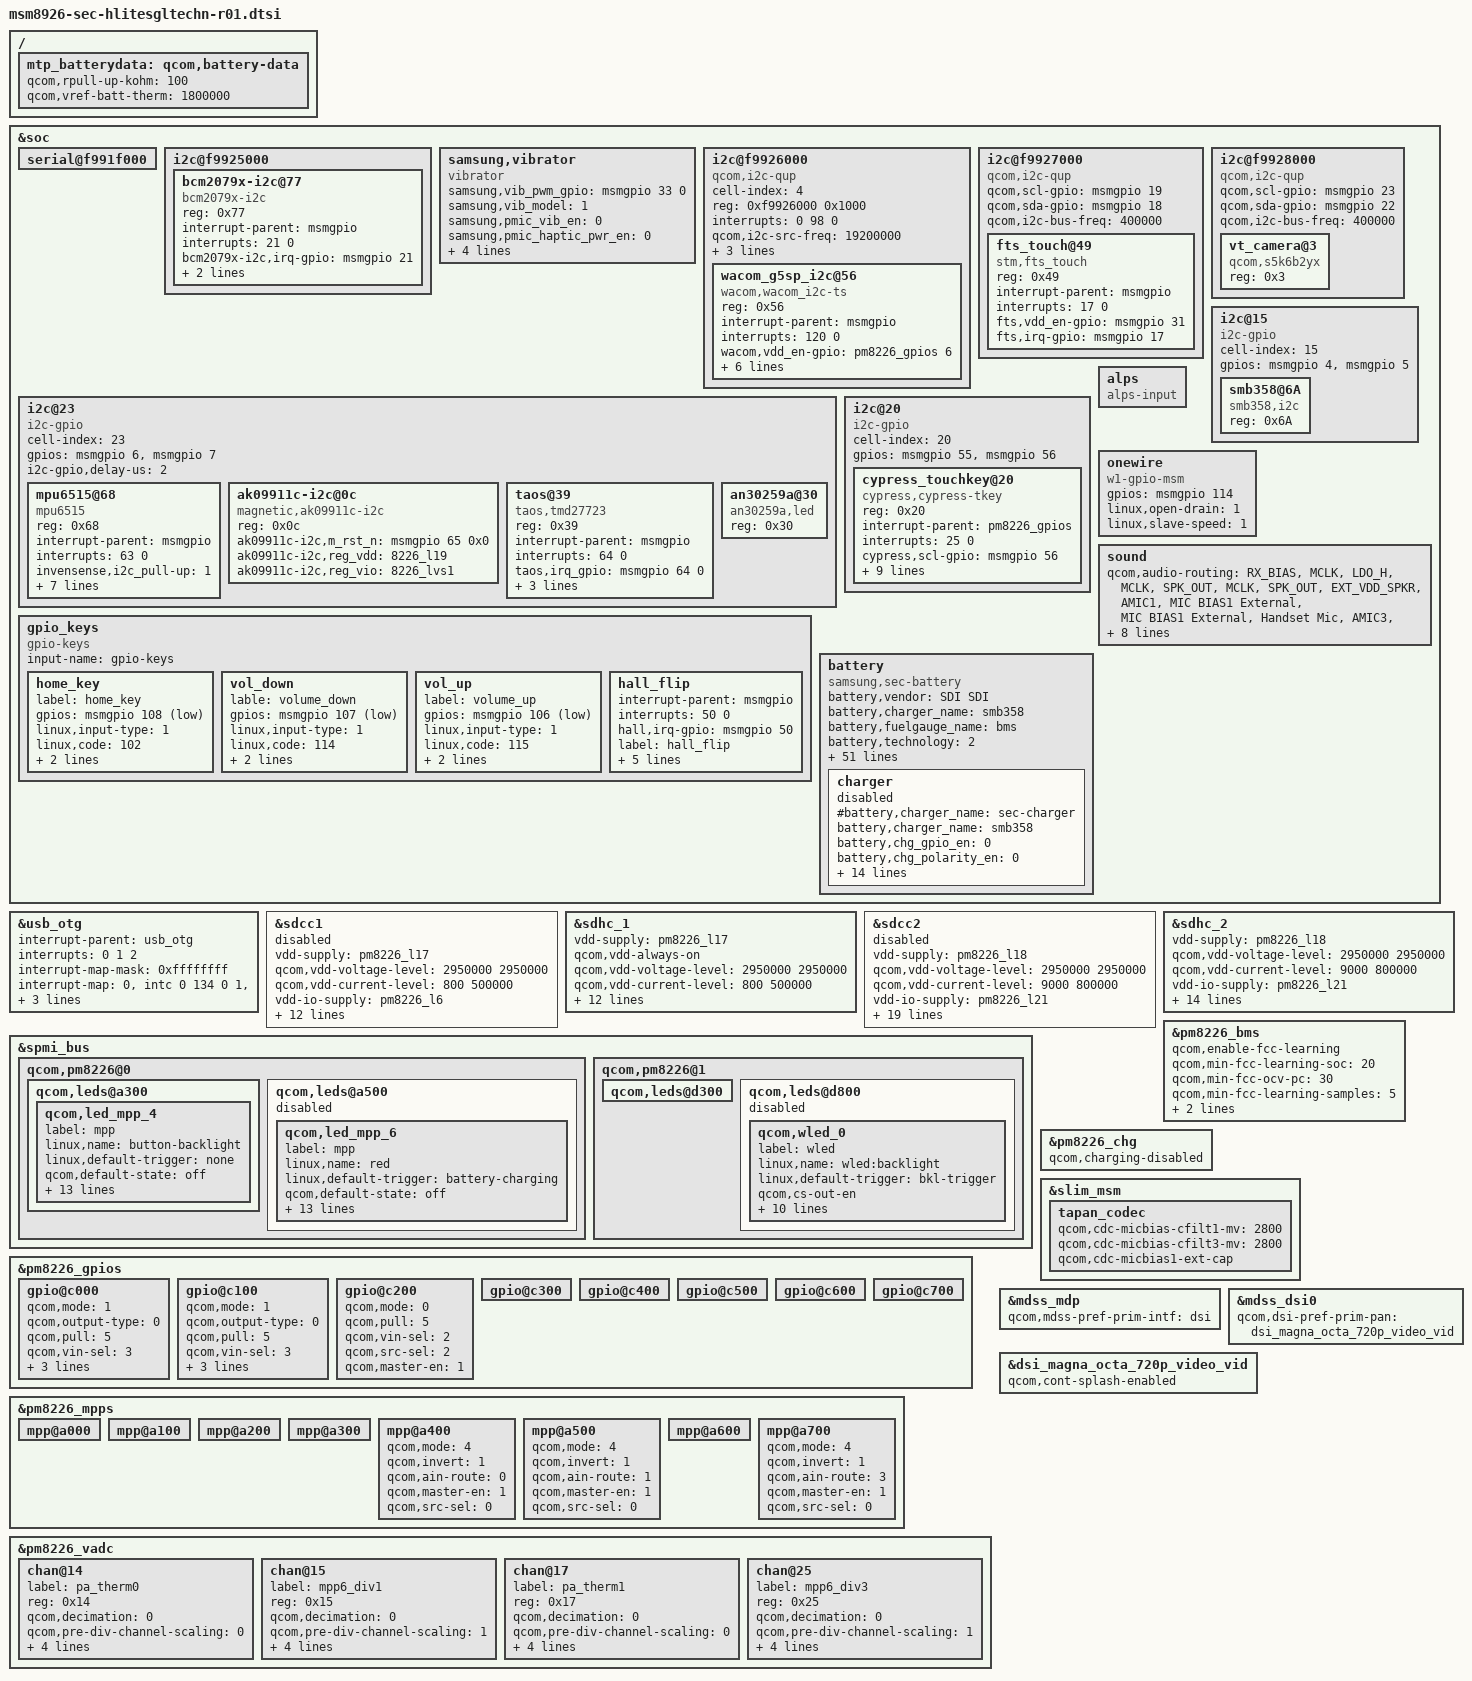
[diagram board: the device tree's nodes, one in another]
/* Copyright (c) 2013, The Linux Foundation. All rights reserved.
 *
 * This program is free software; you can redistribute it and/or modify
 * it under the terms of the GNU General Public License version 2 and
 * only version 2 as published by the Free Software Foundation.
 *
 * This program is distributed in the hope that it will be useful,
 * but WITHOUT ANY WARRANTY; without even the implied warranty of
 * MERCHANTABILITY or FITNESS FOR A PARTICULAR PURPOSE.  See the
 * GNU General Public License for more details.
 */

/include/ "dsi_panel_sharp_720p_video-r01.dtsi"
/include/ "msm8926-camera-sensor-mtp-hllte-r01.dtsi"
/include/ "msm8926-sm5502.dtsi"

&soc {
	serial@f991f000 {
		status = "ok";
	}; 


	i2c@f9925000 {
		bcm2079x-i2c@77 {
			compatible = "bcm2079x-i2c";
			reg = <0x77>;
			interrupt-parent = <&msmgpio>;
           		 interrupts = <21 0>;
			bcm2079x-i2c,irq-gpio = <&msmgpio 21 0x00>;
			bcm2079x-i2c,en-gpio = <&msmgpio 20 0x00>;
			bcm2079x-i2c,wake-gpio = <&msmgpio 62 0x00>;
			};
		};

		samsung,vibrator{
			compatible = "vibrator";
			samsung,vib_pwm_gpio = <&msmgpio 33 0>;
			samsung,vib_model = <1>;
			samsung,pmic_vib_en = <0>;
			samsung,pmic_haptic_pwr_en = <0>;
			samsung,is_pmic_vib_pwm = <0>;
			samsung,is_pmic_vib_en = <0>;
			samsung,pwm_period_us = <40>;
			samsung,duty_us = <36>;
			status = "ok";
    			};
	   
	i2c@f9926000 {
		cell-index = <4>;
		compatible = "qcom,i2c-qup";
		reg = <0xf9926000 0x1000>;
		#address-cells = <1>;
		#size-cells = <0>;
		reg-names = "qup_phys_addr";
		interrupts = <0 98 0>;
		interrupt-names = "qup_err_intr";
		qcom,i2c-src-freq = <19200000>;
		qcom,i2c-bus-freq = <400000>;
		qcom,scl-gpio = <&msmgpio 15 0>;
		qcom,sda-gpio = <&msmgpio 14 0>;
	
		wacom_g5sp_i2c@56 {
			compatible = "wacom,wacom_i2c-ts";
			reg = <0x56>;
			interrupt-parent = <&msmgpio>;
			interrupts = <120 0>;
			wacom,vdd_en-gpio = <&pm8226_gpios 6 0x00>;
			wacom,irq-gpio = <&msmgpio 120 0x00>;
			wacom,insert-pull-up = <1>;
			wacom,sense-gpio = <&msmgpio 54 0x1>;
			wacom,reset_n-gpio = <&msmgpio 13 0x00>;
			wacom,pen_fwe1-gpio = <&msmgpio 119 0x00>;
			wacom,pen_pdct-gpio = <&msmgpio 110 0x00>;
			};
		};

	
	i2c@f9927000 { 
		compatible = "qcom,i2c-qup";
		qcom,scl-gpio = <&msmgpio 19 0>;
		qcom,sda-gpio = <&msmgpio 18 0>;
		qcom,i2c-bus-freq = <400000>;
		fts_touch@49 {
			compatible = "stm,fts_touch";
			reg = <0x49>;
			interrupt-parent = <&msmgpio>;
			interrupts = <17 0>;
			fts,vdd_en-gpio = <&msmgpio 31 0x00>;
			fts,irq-gpio = <&msmgpio 17 0x00>;
			/* vddo-supply = <&pm8226_lvs1>; */
			};
		};
	
		i2c@f9928000 { 
			compatible = "qcom,i2c-qup";
			qcom,scl-gpio = <&msmgpio 23 0>;
			qcom,sda-gpio = <&msmgpio 22 0>;
			qcom,i2c-bus-freq = <400000>;
			vt_camera@3 {
					compatible = "qcom,s5k6b2yx";
					reg = <0x3>;
				};
		};
	
	i2c@23 {
		cell-index = <23>;
		compatible = "i2c-gpio";
		gpios = <&msmgpio 6 0 /* sda */
		&msmgpio 7 0 /* scl */
		>;
                i2c-gpio,delay-us = <2>;
		mpu6515@68 {
			compatible = "mpu6515";
			reg = <0x68>;
			interrupt-parent = <&msmgpio>;
			interrupts = <63 0>;
			invensense,i2c_pull-up = <1>;
			invensense,reg_vdd = "8226_l19";
			invensense,reg_vio = "8226_lvs1";
	             	invensense,irq-gpio= <&msmgpio 63 0x1>;
			invensense,scl-gpio = <&msmgpio 7 0x00>;
			invensense,sda-gpio = <&msmgpio 6 0x00>;
			invensense,acc_cal_path = "/efs/calibration_data";
			invensense,gyro_cal_path = "/efs/gyro_cal_data";
		};
		ak09911c-i2c@0c {
			compatible = "magnetic,ak09911c-i2c";
			reg = <0x0c>;
			ak09911c-i2c,m_rst_n = <&msmgpio 65 0x0>;
			ak09911c-i2c,reg_vdd = "8226_l19";
			ak09911c-i2c,reg_vio = "8226_lvs1";
		};
		taos@39 {
			compatible = "taos,tmd27723";
			reg = <0x39>;
			interrupt-parent = <&msmgpio>;
			interrupts = <64 0>;
			taos,irq_gpio = <&msmgpio 64 0>;
			taos,en = <&pm8226_gpios 8 0x00>;
			taos,prox_cal_path = "/efs/prox_cal";
			taos,vdd_2p85 = "8226_l19";
		};
		an30259a@30 {
			compatible = "an30259a,led";
			reg = <0x30>;
		};
	};
	
	i2c@15 {
		cell-index = <15>;
		compatible = "i2c-gpio";
		gpios = <&msmgpio 4 0  /* sda */
				&msmgpio 5 0   /* scl */
				>;

		smb358@6A {
			compatible = "smb358,i2c";
			reg = <0x6A>;
		};
		};

	i2c@20 {
		cell-index = <20>;
		compatible = "i2c-gpio";
		gpios = <&msmgpio 55 0 /* sda */
		&msmgpio 56 0 /* scl */
		>;

		cypress_touchkey@20 {
			compatible = "cypress,cypress-tkey";
			reg = <0x20>;
			interrupt-parent = <&pm8226_gpios>;
			interrupts = <25 0>;
			/* vdd_led-supply = <&pm8941_l13>;
			vcc_en-supply = <&pm8941_lvs3>; */
			cypress,scl-gpio = <&msmgpio 56 0x00>;
			cypress,sda-gpio = <&msmgpio 55 0x00>;
			cypress,irq-gpio = <&msmgpio 24 0x1>;
			
			cypress,touchkey_i2cldo-gpio = <&pm8226_gpios 2 0x00>;			
			cypress,touchkey_vddldo-gpio = <&pm8226_gpios 3 0x00>;			
			
			cypress,twotouch_id-gpio = <&pm8226_gpios 7 0x00>;	
			cypress,twotouch_rst-gpio = <&msmgpio 36 0x00>;	
			cypress,twotouch_grip-gpio = <&msmgpio 49 0x00>;	
			
			cypress,tkey-keycodes = <139 158>;
			cypress,i2c-pull-up = <1>;
		};
	};
	

	gpio_keys {
		compatible = "gpio-keys";
		input-name = "gpio-keys";

		home_key {
			label = "home_key";
			gpios = <&msmgpio 108 0x1>;
			linux,input-type = <1>;
			linux,code = <102>;
			gpio-key,wakeup;
			debounce-interval = <15>;
		};

		vol_down {
			lable = "volume_down";
			gpios = <&msmgpio 107 0x1>;
			linux,input-type = <1>;
			linux,code = <114>;
			gpio-key,wakeup;
			debounce-interval = <15>;
		};

		vol_up {
			label = "volume_up";
			gpios = <&msmgpio 106 0x1>;
			linux,input-type = <1>;
			linux,code = <115>;
			gpio-key,wakeup;
			debounce-interval = <15>;
		};

		hall_flip {
			interrupt-parent = <&msmgpio>;
			interrupts = <50 0>;
			hall,irq-gpio = <&msmgpio 50 0x00>;

			label = "hall_flip";
			gpios = <&msmgpio 50 0>;
			linux,input-type = <1>;
			linux,code = <0x15>;
			gpio-key,wakeup;
			debounce-interval = <15>;
		};
	};
	alps {
			compatible = "alps-input";
	};
	onewire {
		compatible = "w1-gpio-msm";
		gpios = <&msmgpio 114 0x00>;
		linux,open-drain = <1>;
		linux,slave-speed = <1>;
	};
/*
	spi@f9923000 {
		ethernet-switch@3 {
			compatible = "micrel,ks8851";
			reg = <3>;
			interrupt-parent = <&msmgpio>;
			interrupts = <115 0x8>;
			spi-max-frequency = <4800000>;
			rst-gpio = <&msmgpio 114 0>;
			vdd-io-supply = <&pm8226_lvs1>;
			vdd-phy-supply = <&pm8226_lvs1>;
		};
	};
*/

	sound {
		qcom,audio-routing =
			"RX_BIAS", "MCLK",
			"LDO_H", "MCLK",
			"SPK_OUT", "MCLK",
			"SPK_OUT", "EXT_VDD_SPKR",
			"AMIC1", "MIC BIAS1 External",
			"MIC BIAS1 External", "Handset Mic",
			"AMIC3", "MIC BIAS3 External",
			"MIC BIAS3 External", "Sub Mic",					
			"AMIC2", "MIC BIAS2 External",
			"MIC BIAS2 External", "Headset Mic",
			"AMIC4", "MIC BIAS2 External",
			"MIC BIAS2 External", "ANCRight Headset Mic",
			"AMIC5", "MIC BIAS2 External",
			"MIC BIAS2 External", "ANCLeft Headset Mic";

		qcom,cdc-mclk-gpios = <&pm8226_gpios 1 0>;
		/*qcom,cdc-vdd-spkr-gpios = <&pm8226_gpios 2 0>;*/
	};
	
	battery {
		status = "okay";
		compatible = "samsung,sec-battery";
		battery,vendor = "SDI SDI";
		battery,charger_name = "smb358";
		battery,fuelgauge_name = "bms";
		battery,technology = <2>; /* POWER_SUPPLY_TECHNOLOGY_LION */
		battery,ta_int = <&msmgpio 51 0x1>;
		battery,ta_irq_attr = <0x3>;
		battery,chip_vendor = "QCOM";
		battery,temp_adc_type = <1>; /* SEC_BATTERY_ADC_TYPE_AP */

		battery,polling_time = <10 30 30 30 3600>;

		battery,adc_check_count = <5>;

		battery,cable_check_type = <4>; /* SEC_BATTERY_CABLE_CHECK_PSY */
		battery,cable_source_type = <3>; /* SEC_BATTERY_CABLE_SOURCE_EXTERNAL | SEC_BATTERY_CABLE_SOURCE_CALLBACK */
		battery,event_check;
		battery,event_waiting_time = <600>;
		battery,polling_type = <1>; /* SEC_BATTERY_MONITOR_ALARM */
		battery,monitor_initial_count = <3>;

		battery,battery_check_type = <4>; /* SEC_BATTERY_CHECK_FUELGAUGE */
		battery,check_count = <0>;
		battery,check_adc_max = <1440>;
		battery,check_adc_min = <0>;

		battery,ovp_uvlo_check_type = <3>; /* SEC_BATTERY_OVP_UVLO_CHGPOLLING */

		battery,thermal_source = <0>; /* SEC_BATTERY_THERMAL_SOURCE_FG */

		battery,temp_table_adc = <27281 27669 28178 28724 29342 30101 30912 31807 32823 33858 34950 36049 37054
			38025 38219 38448 38626 38795 38989 39229 39540 39687 39822 40523 41123 41619>;
		battery,temp_table_data = <700 650 600 550 500 450 400 350 300 250 200 150 100
			50 40 30 20 10 0 (-10) (-30) (-40) (-50) (-100) (-150) (-200)>;
		battery,temp_check_type = <2>; /* SEC_BATTERY_TEMP_CHECK_TEMP */
		battery,temp_check_count = <1>;
		battery,temp_high_threshold_event = <600>;
		battery,temp_high_recovery_event = <460>;
		battery,temp_low_threshold_event = <(-50)>;
		battery,temp_low_recovery_event = <0>;
		battery,temp_high_threshold_normal = <600>;
		battery,temp_high_recovery_normal = <460>;
		battery,temp_low_threshold_normal = <(-50)>;
		battery,temp_low_recovery_normal = <0>;
		battery,temp_high_threshold_lpm = <600>;
		battery,temp_high_recovery_lpm = <460>;
		battery,temp_low_threshold_lpm = <(-50)>;
		battery,temp_low_recovery_lpm = <0>;
		battery,full_check_type = <7>; /* SEC_BATTERY_FULLCHARGED_CHGPSY */
		battery,full_check_type_2nd = <3>; /* SEC_BATTERY_FULLCHARGED_TIME */
		battery,full_check_count = <1>;
		battery,chg_gpio_full_check = <0>;
		battery,chg_polarity_full_check = <1>;

		/* SEC_BATTERY_FULL_CONDITION_SOC |
		   SEC_BATTERY_FULL_CONDITION_NOTIMEFULL |
		   SEC_BATTERY_FULL_CONDITION_VCELL */
		battery,full_condition_type = <13>;
		battery,full_condition_soc = <97>;
		battery,full_condition_vcell = <4300>;

		battery,recharge_check_count = <1>;
		battery,recharge_condition_type = <4>; /* SEC_BATTERY_RECHARGE_CONDITION_VCELL */
		battery,recharge_condition_soc = <98>;
		battery,recharge_condition_vcell = <4300>;

		battery,charging_total_time = <21600>;
		battery,recharging_total_time = <5400>;
		battery,charging_reset_time = <0>;

		charger{
			status = "disable";
			/* Charger */
			#battery,charger_name = "sec-charger";
			battery,charger_name = "smb358";
			battery,chg_gpio_en = <0>;
			battery,chg_polarity_en = <0>;
			battery,chg_gpio_status = <0>;
			battery,chg_polarity_status = <0>;
			battery,chg_float_voltage = <4350>;
			battery,ovp_uvlo_check_type = <3>; /* SEC_BATTERY_OVP_UVLO_CHGPOLLING */
			battery,full_check_type = <7>; /* SEC_BATTERY_FULLCHARGED_CHGPSY */
			battery,chg_functions_setting = <1>; /* AICL */

			battery,input_current_limit = <1800 460 460 1800 460 900 1000 460 460 1000 650 1800 1800 460 400 700 1300 300 1000 1800 460>;
			battery,fast_charging_current = <2000 0 460 2000 460 1200 1000 460 0 1200 750 2000 2000 0 400 700 1300 300 1000 2000 0>;
			battery,full_check_current_1st = <200 0 200 200 200 200 200 200 0 200 200 200 200 0 200 200 200 200 200 200 0>;
			battery,full_check_current_2nd = <2400 0 2400 2400 2400 2400 2400 2400 0 2400 2400 2400 2400 0 2400 2400 2400 2400 2400 2400 0>;
		};
	};
};

&usb_otg {
	#address-cells = <0>;
	interrupt-parent = <&usb_otg>;
	interrupts = <0 1 2>;
	#interrupt-cells = <1>;
	interrupt-map-mask = <0xffffffff>;
	interrupt-map = <0 &intc 0 134 0
			1 &intc 0 140 0
			2 &spmi_bus 0x0 0x0 0x9 0x0>;
	interrupt-names = "core_irq", "async_irq", "pmic_id_irq";

	qcom,hsusb-otg-mode = <3>;
	vbus_otg-supply = <&pm8226_chg_otg>;
};

&sdcc1 {
	vdd-supply = <&pm8226_l17>;
	qcom,vdd-voltage-level = <2950000 2950000>;
	qcom,vdd-current-level = <800 500000>;

	vdd-io-supply = <&pm8226_l6>;
	qcom,vdd-io-always-on;
	qcom,vdd-io-voltage-level = <1800000 1800000>;
	qcom,vdd-io-current-level = <250 154000>;

	qcom,pad-pull-on = <0x0 0x3 0x3>; /* no-pull, pull-up, pull-up */
	qcom,pad-pull-off = <0x0 0x3 0x3>; /* no-pull, pull-up, pull-up */
	qcom,pad-drv-on = <0x4 0x4 0x4>; /* 10mA, 10mA, 10mA */
	qcom,pad-drv-off = <0x0 0x0 0x0>; /* 2mA, 2mA, 2mA */

	qcom,clk-rates = <400000 25000000 50000000 100000000 200000000>;
	qcom,sup-voltages = <2950 2950>;

	qcom,bus-speed-mode = "HS200_1p8v", "DDR_1p8v";
	qcom,nonremovable;

	status = "disabled";
};

&sdhc_1 {
	vdd-supply = <&pm8226_l17>;
	qcom,vdd-always-on;
	qcom,vdd-voltage-level = <2950000 2950000>;
	qcom,vdd-current-level = <800 500000>;

	vdd-io-supply = <&pm8226_l6>;
	qcom,vdd-io-always-on;
	qcom,vdd-io-voltage-level = <1800000 1800000>;
	qcom,vdd-io-current-level = <250 154000>;

	qcom,pad-pull-on = <0x0 0x3 0x3>; /* no-pull, pull-up, pull-up */
	qcom,pad-pull-off = <0x0 0x3 0x3>; /* no-pull, pull-up, pull-up */
	qcom,pad-drv-on = <0x4 0x4 0x4>; /* 10mA, 10mA, 10mA */
	qcom,pad-drv-off = <0x0 0x0 0x0>; /* 2mA, 2mA, 2mA */

	qcom,clk-rates = <400000 25000000 50000000 100000000 200000000>;
	qcom,bus-speed-mode = "HS200_1p8v", "DDR_1p8v";
	qcom,nonremovable;

	status = "ok";
};

&sdcc2 {
	vdd-supply = <&pm8226_l18>;
	qcom,vdd-voltage-level = <2950000 2950000>;
	qcom,vdd-current-level = <9000 800000>;

	vdd-io-supply = <&pm8226_l21>;
	qcom,vdd-io-voltage-level = <1800000 2950000>;
	qcom,vdd-io-current-level = <6 22000>;

	qcom,pad-pull-on = <0x0 0x3 0x3>; /* no-pull, pull-up, pull-up */
	qcom,pad-pull-off = <0x0 0x3 0x3>; /* no-pull, pull-up, pull-up */
	qcom,pad-drv-on = <0x4 0x4 0x4>; /* 10mA, 10mA, 10mA */
	qcom,pad-drv-off = <0x0 0x0 0x0>; /* 2mA, 2mA, 2mA */

	qcom,clk-rates = <400000 25000000 50000000 100000000 200000000>;
	qcom,sup-voltages = <2950 2950>;

	qcom,xpc;
	qcom,bus-speed-mode = "SDR12", "SDR25", "SDR50", "DDR50", "SDR104";
	qcom,current-limit = <600>; #address-cells = <0>; interrupt-parent = <&sdcc2>;
	interrupts = <0 1 2>;
	#interrupt-cells = <1>;
	interrupt-map-mask = <0xffffffff>;
	interrupt-map = <0 &intc 0 125 0
			1 &intc 0 220 0
			2 &msmgpio 38 0x3>;
	interrupt-names = "core_irq", "bam_irq", "status_irq";
	cd-gpios = <&msmgpio 38 0x1>;

	status = "disabled";
};

&sdhc_2 {
	vdd-supply = <&pm8226_l18>;
	qcom,vdd-voltage-level = <2950000 2950000>;
	qcom,vdd-current-level = <9000 800000>;

	vdd-io-supply = <&pm8226_l21>;
	qcom,vdd-io-voltage-level = <1800000 2950000>;
	qcom,vdd-io-current-level = <6 22000>;

	qcom,pad-pull-on = <0x0 0x3 0x3>; /* no-pull, pull-up, pull-up */
	qcom,pad-pull-off = <0x0 0x1 0x1>; /* no-pull, pull-down, pull-down */
	qcom,pad-drv-on = <0x4 0x4 0x4>; /* 10mA, 10mA, 10mA */
	qcom,pad-drv-off = <0x0 0x0 0x0>; /* 2mA, 2mA, 2mA */

	qcom,clk-rates = <400000 25000000 50000000 100000000 200000000>;

	#address-cells = <0>;
	interrupt-parent = <&sdhc_2>;
	interrupts = <0 1 2>;
	#interrupt-cells = <1>;
	interrupt-map-mask = <0xffffffff>;
	interrupt-map = <0 &intc 0 125 0
			1 &intc 0 221 0
			2 &msmgpio 38 0x3>;
	interrupt-names = "hc_irq", "pwr_irq", "status_irq";
	cd-gpios = <&msmgpio 38 0x1>;

	status = "ok";
};

&spmi_bus {
	qcom,pm8226@0 {
		/*qcom,leds@a100 {   this node is not used.
			status = "disabled";
			qcom,led_mpp_2 {
				label = "mpp";
				linux,name = "green";
				linux,default-trigger = "battery-full";
				qcom,default-state = "off";
				qcom,max-current = <40>;
				qcom,current-setting = <5>;
				qcom,id = <6>;
				qcom,mode = "manual";
				qcom,source-sel = <1>;
				qcom,mode-ctrl = <0x60>;
			};
		};*/
		qcom,leds@a300 {
			status = "okay";
			qcom,led_mpp_4 {
				label = "mpp";
				linux,name = "button-backlight";
				linux,default-trigger = "none";
				qcom,default-state = "off";
				qcom,max-current = <40>;
				qcom,current-setting = <40>;
				qcom,id = <6>;
				qcom,mode = "pwm";
				qcom,pwm-us = <1000>;
				qcom,source-sel = <8>;
				qcom,mode-ctrl = <0x60>;
				qcom,pwm-channel = <0>;
				qcom,start-idx = <1>;
				qcom,ramp-step-ms = <120>;
				qcom,duty-pcts = [00 00 00 00 00
						  00 00 00 00 00
						  50 00 00 00 00
						  00 00 00 00 00
						  00];
				qcom,use-blink;
			};
		};
		qcom,leds@a500 {
			status = "disabled";
			qcom,led_mpp_6 {
				label = "mpp";
				linux,name = "red";
				linux,default-trigger = "battery-charging";
				qcom,default-state = "off";
				qcom,max-current = <40>;
				qcom,current-setting = <5>;
				qcom,id = <6>;
				qcom,mode = "pwm";
				qcom,pwm-us = <1000>;
				qcom,mode-ctrl = <0x60>;
				qcom,source-sel = <10>;
				qcom,pwm-channel = <5>;
				qcom,start-idx = <1>;
				qcom,ramp-step-ms = <120>;
				qcom,duty-pcts = [00 00 00 00 00
						  00 00 00 00 00
						  50 00 00 00 00
						  00 00 00 00 00
						  00];
				qcom,use-blink;
			};
		};
	};

	qcom,pm8226@1 {
                qcom,leds@d300 {
                        status = "okay";
                };

		qcom,leds@d800 {
			status = "disabled";/*If WLED is not used for Backlight control*/
			qcom,wled_0 {		/*for TFT Panel, this to be disabled */
				label = "wled";
				linux,name = "wled:backlight";
				linux,default-trigger = "bkl-trigger";
				qcom,cs-out-en;
				qcom,op-fdbck = <1>;
				qcom,default-state = "off";
				qcom,max-current = <20>;
				qcom,ctrl-delay-us = <0>;
				qcom,boost-curr-lim = <3>;
				qcom,cp-sel = <0>;
				qcom,switch-freq = <11>;
				qcom,ovp-val = <0>;
				qcom,num-strings = <1>;
				qcom,id = <0>;
			};
		};
	};
};

&pm8226_gpios {
	gpio@c000 { /* GPIO 1 */
		/* XO_PMIC_CDC_MCLK enable for tapan codec */
		qcom,mode = <1>;		/* Digital output */
		qcom,output-type = <0>;	/* CMOS logic */
		qcom,pull = <5>;		/* QPNP_PIN_PULL_NO*/
		qcom,vin-sel = <3>;		/* QPNP_PIN_VIN3 */
		qcom,out-strength = <3>;/* QPNP_PIN_OUT_STRENGTH_HIGH */
		qcom,src-sel = <2>;		/* QPNP_PIN_SEL_FUNC_1 */
		qcom,master-en = <1>;	/* Enable GPIO */
	};

	gpio@c100 { /* GPIO 2 */
		qcom,mode = <1>;
		qcom,output-type = <0>;
		qcom,pull = <5>;
		qcom,vin-sel = <3>;
		qcom,out-strength = <3>;
		qcom,src-sel = <2>;
		qcom,master-en = <1>;
	};

	gpio@c200 { /* GPIO 3 */
		qcom,mode = <0>;		/* QPNP_PIN_MODE_DIG_IN */
		qcom,pull = <5>;		/* QPNP_PIN_PULL_NO */
		qcom,vin-sel = <2>;		/* QPNP_PIN_VIN2 */
		qcom,src-sel = <2>;		/* QPNP_PIN_SEL_FUNC_1 */
		qcom,master-en = <1>;
	};

	gpio@c300 { /* GPIO 4 */
	};

	gpio@c400 { /* GPIO 5 */
	};

	gpio@c500 { /* GPIO 6 */
	};

	gpio@c600 { /* GPIO 7 */
	};

	gpio@c700 { /* GPIO 8 */
	};
};

&pm8226_mpps {
	mpp@a000 { /* MPP 1 */
	};

	mpp@a100 { /* MPP 2 */
	};

	mpp@a200 { /* MPP 3 */
	};

	mpp@a300 { /* MPP 4 */
	};

	mpp@a400 { /* MPP 5 */
		/* PA_THERM0 config */
		qcom,mode = <4>; /* AIN input */
		qcom,invert = <1>; /* Enable MPP */
		qcom,ain-route = <0>; /* AMUX 5 */
		qcom,master-en = <1>;
		qcom,src-sel = <0>; /* Function constant */
	};

	mpp@a500 { /* MPP 6 */
		qcom,mode = <4>; /* AIN input */
		qcom,invert = <1>; /* Enable MPP */
		qcom,ain-route = <1>; /* AMUX 6 */
		qcom,master-en = <1>;
		qcom,src-sel = <0>; /* Function constant */
	};

	mpp@a600 { /* MPP 7 */
	};

	mpp@a700 { /* MPP 8 */
		/* PA_THERM1 config */
		qcom,mode = <4>; /* AIN input */
		qcom,invert = <1>; /* Enable MPP */
		qcom,ain-route = <3>; /* AMUX 8 */
		qcom,master-en = <1>;
		qcom,src-sel = <0>; /* Function constant */
	};
};

&pm8226_vadc {
	chan@14 {
		label = "pa_therm0";
		reg = <0x14>;
		qcom,decimation = <0>;
		qcom,pre-div-channel-scaling = <0>;
		qcom,calibration-type = "ratiometric";
		qcom,scale-function = <2>;
		qcom,hw-settle-time = <2>;
		qcom,fast-avg-setup = <0>;
	};

	chan@15 {
		label = "mpp6_div1";
		reg = <0x15>;
		qcom,decimation = <0>;
		qcom,pre-div-channel-scaling = <1>;
		qcom,calibration-type = "absolute";
		qcom,scale-function = <0>;
		qcom,hw-settle-time = <0>;
		qcom,fast-avg-setup = <0>;
	};

	chan@17 {
		label = "pa_therm1";
		reg = <0x17>;
		qcom,decimation = <0>;
		qcom,pre-div-channel-scaling = <0>;
		qcom,calibration-type = "ratiometric";
		qcom,scale-function = <2>;
		qcom,hw-settle-time = <2>;
		qcom,fast-avg-setup = <0>;
	};
	chan@25 {
		label = "mpp6_div3";
		reg = <0x25>;
		qcom,decimation = <0>;
		qcom,pre-div-channel-scaling = <1>;
		qcom,calibration-type = "absolute";
		qcom,scale-function = <0>;
		qcom,hw-settle-time = <0>;
		qcom,fast-avg-setup = <0>;
	};
};

/ {
	mtp_batterydata: qcom,battery-data {
		qcom,rpull-up-kohm = <100>;
		qcom,vref-batt-therm = <1800000>;

		/include/ "batterydata-palladium.dtsi"
		/include/ "batterydata-mtp-3000mah.dtsi"
	};
};

&pm8226_bms {
	status = "ok";
	qcom,enable-fcc-learning;
	qcom,min-fcc-learning-soc = <20>;
	qcom,min-fcc-ocv-pc = <30>;
	qcom,min-fcc-learning-samples = <5>;
	qcom,fcc-resolution = <10>;
	qcom,battery-data = <&mtp_batterydata>;
};

&pm8226_chg {
	qcom,charging-disabled;
};

&slim_msm {
	tapan_codec {
		qcom,cdc-micbias-cfilt1-mv = <2800>;
		qcom,cdc-micbias-cfilt3-mv = <2800>;
		qcom,cdc-micbias1-ext-cap;
	};
};

&mdss_mdp {
	qcom,mdss-pref-prim-intf = "dsi";
};

&mdss_dsi0 {
	qcom,dsi-pref-prim-pan = <&dsi_magna_octa_720p_video_vid>;
};

&dsi_magna_octa_720p_video_vid {
	qcom,cont-splash-enabled;
};
